VERSION ""

NS_ :

BS_:

BU_: DashBoard Engine Control Blinkers
VAL_TABLE_ Start 1 "On" 0 "Off" ;
VAL_TABLE_ ParkingBreak 1 "Parking Break Set" 0 "Parking Break Not Set" ;
VAL_TABLE_ Gear 6 "Reverse Gear" 5 "Gear 5" 4 "Gear 4" 3 "Gear 3" 2 "Gear 2" 1 "Gear 1" 0 "Neutral" ;
VAL_TABLE_ BrakePedal 1 "Brake Pedal Pressed" 0 "Brake Pedal Released" ;
VAL_TABLE_ blinkers 1 "Active" 0 "Inactive" ;

BO_ 1023 FrmStart: 1 DashBoard
 SG_ sigStart : 0|1@1+ (1,0) [0|1] ""  DashBoard,Engine,Control,Blinkers

BO_ 768 FrmEngine: 2 Engine
 SG_ speedEngine : 8|8@1+ (27.4509803921569,0) [0|7000] "RPM"  DashBoard
 SG_ gear : 0|3@1+ (1,0) [0|7] ""  DashBoard

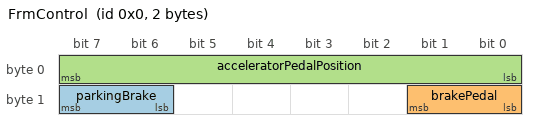
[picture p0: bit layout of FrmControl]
BO_ 0 FrmControl: 2 Control
 SG_ parkingBrake : 14|2@1+ (1,0) [0|3] ""  DashBoard,Engine
 SG_ brakePedal : 8|2@1+ (1,0) [0|3] ""  Engine
 SG_ acceleratorPedalPosition : 0|8@1+ (0.392156862745098,0) [0|100] "%"  Engine

BO_ 1008 FrmBlinkers: 1 DashBoard
 SG_ blinkerR : 1|1@1+ (1,0) [0|1] ""  Blinkers
 SG_ blinkerL : 0|1@1+ (1,0) [0|1] ""  Blinkers

EV_ BlinkerR_pushbutton: 0 [0|1] "" 0 1 DUMMY_NODE_VECTOR1  Blinkers;

EV_ BlinkerL_pushbutton: 0 [0|1] "" 0 2 DUMMY_NODE_VECTOR1  Blinkers;

EV_ Gear_value: 0 [0|6] "gear" 0 3 DUMMY_NODE_VECTOR2  Engine;

EV_ Engine_RPM_value: 0 [0|28672] "rpm" 0 4 DUMMY_NODE_VECTOR2  Engine;

EV_ Speed_Indicator_value: 0 [0|768] "km/h" 0 5 DUMMY_NODE_VECTOR2  Engine;

EV_ BlinkerR_value: 0 [0|1] "" 0 6 DUMMY_NODE_VECTOR2  Blinkers;

EV_ BlinkerL_value: 0 [0|1] "" 0 7 DUMMY_NODE_VECTOR2  Blinkers;

BA_DEF_ BU_  "NodeLayerModule" STRING ;
BA_DEF_ BU_  "NodeLayerModules" STRING ;
BA_DEF_ BO_  "GenMsgILSupport" ENUM  "No","Yes";
BA_DEF_  "NmBaseAddress" HEX 1024 1087;
BA_DEF_  "BusType" STRING ;
BA_DEF_ BO_  "GenMsgCycleTime" INT 0 50000;
BA_DEF_ BO_  "GenMsgSendType" ENUM  "Cyclic","NotUsed","NotUsed","NotUsed","NotUsed","Cyclic","NotUsed","IfActive","NoMsgSendType","NotUsed","vector_leerstring";
BA_DEF_ SG_  "GenSigSendType" ENUM  "Cyclic","OnWrite","OnWriteWithRepetition","OnChange","OnChangeWithRepetition","IfActive","IfActiveWithRepetition","NoSigSendType","NotUsed","NotUsed","NotUsed","NotUsed","NotUsed";
BA_DEF_DEF_  "NodeLayerModule" "CANoeILNLVector.dll";
BA_DEF_DEF_  "NodeLayerModules" "CANoeILNLVector.dll";
BA_DEF_DEF_  "GenMsgILSupport" "Yes";
BA_DEF_DEF_  "NmBaseAddress" 1024;
BA_DEF_DEF_  "BusType" "CAN";
BA_DEF_DEF_  "GenMsgCycleTime" 0;
BA_DEF_DEF_  "GenMsgSendType" "NoMsgSendType";
BA_DEF_DEF_  "GenSigSendType" "Cyclic";
BA_ "GenMsgSendType" BO_ 1023 7;
BA_ "GenMsgSendType" BO_ 768 0;
BA_ "GenMsgCycleTime" BO_ 768 100;
BA_ "GenMsgSendType" BO_ 0 0;
BA_ "GenMsgCycleTime" BO_ 0 50;
BA_ "GenSigSendType" SG_ 1023 sigStart 3;
VAL_ 1023 sigStart 1 "On" 0 "Off" ;
VAL_ 768 gear 6 "Reverse Gear" 5 "Gear 5" 4 "Gear 4" 3 "Gear 3" 2 "Gear 2" 1 "Gear 1" 0 "Neutral" ;
VAL_ 0 parkingBrake 1 "Parking Break Set" 0 "Parking Break Not Set" ;
VAL_ 0 brakePedal 1 "Brake Pedal Pressed" 0 "Brake Pedal Released" ;
VAL_ 1008 blinkerR 1 "Active" 0 "Inactive" ;
VAL_ 1008 blinkerL 1 "Active" 0 "Inactive" ;
VAL_ Gear_value 6 "Reverse Gear" 5 "Gear 5" 4 "Gear 4" 3 "Gear 3" 2 "Gear 2" 1 "Gear 1" 0 "Neutral" ;
VAL_ BlinkerR_value 1 "Active" 0 "Inactive" ;
VAL_ BlinkerL_value 1 "Active" 0 "Inactive" ;
